# STM32L4S7xx register map
File version: 1.0
Registers are 32-bit, read-write, reset 0x0 unless marked. A register's access mark holds for its fields unless they carry their own. Offsets are from the block's base; [hi:lo] are bit positions; {n}, {i} and the like mark numbered series.

## GFXMMU — GFXMMU registers
Base 0x4002C000
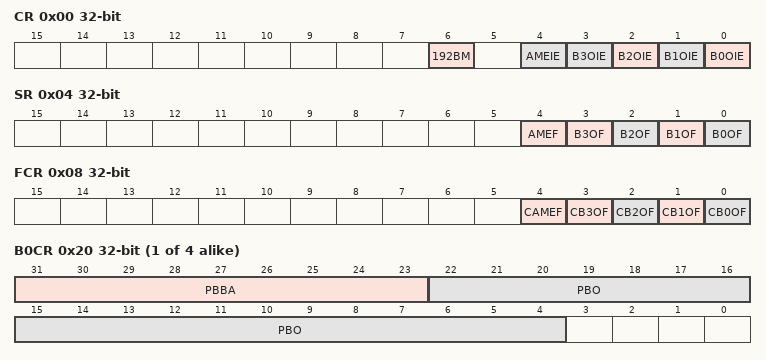
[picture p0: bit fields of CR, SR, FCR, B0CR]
0x00 CR — GFXMMU configuration register
  [6] 192BM — 192 block mode
  [4] AMEIE — AHB master error interrupt enable
  [n] B{n}OIE (n=0..3) — Buffer {n} overflow interrupt enable
0x04 SR — GFXMMU status register
  [4] AMEF — AHB master error flag
  [n] B{n}OF (n=0..3) — Buffer {n} overflow flag
0x08 FCR — GFXMMU flag clear register
  [4] CAMEF — Clear AHB master error flag
  [n] CB{n}OF (n=0..3) — Clear buffer {n} overflow flag
0x10 DVR — GFXMMU default value register
  [31:0] DV — DV[31:0] bits (Default value)
{0x20+4i} B{i}CR (i=0..3) — GFXMMU buffer {i} configuration register
  [31:23] PBBA — PBBA[31:23] bits (Physical buffer base address)
  [22:4] PBO — PB0[22:4] bits (Physical buffer offset)
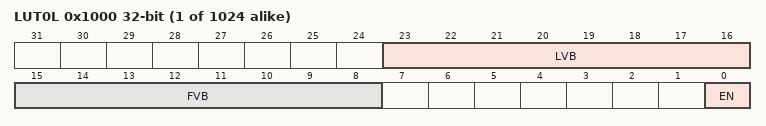
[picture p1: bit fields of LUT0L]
{0x1000+8i} LUT{i}L (i=0..1023) — GFXMMU LUT registers
  [23:16] LVB — LVB[7:0] bits (Last visible block)
  [15:8] FVB — FVB[7:0] bits (First visible block)
  [0] EN — Enable
{0x1004+8i} LUT{i}H (i=0..1023) — GFXMMU LUT registers
  [21:4] LO — LO[21:4] bits (Line offset)

## GPIOA — General Purpose I/O
Base 0x48000000
Same registers: GPIOB 0x48000400, GPIOC 0x48000800, GPIOD 0x48000C00, GPIOE 0x48001000, GPIOF 0x48001400, GPIOG 0x48001800, GPIOH 0x48001C00, GPIOI 0x48002000
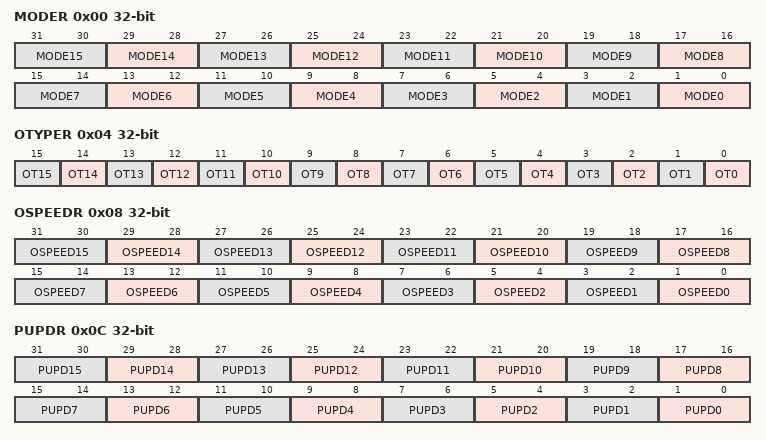
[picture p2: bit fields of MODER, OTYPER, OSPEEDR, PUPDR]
0x00 MODER — GPIO port mode register
  [2n+1:2n] MODE{n} (n=0..15)
0x04 OTYPER — GPIO port output type register
  [n] OT{n} (n=0..15)
0x08 OSPEEDR — GPIO port output speed register
  [2n+1:2n] OSPEED{n} (n=0..15)
0x0C PUPDR — GPIO port pull-up/pull-down register
  [2n+1:2n] PUPD{n} (n=0..15)
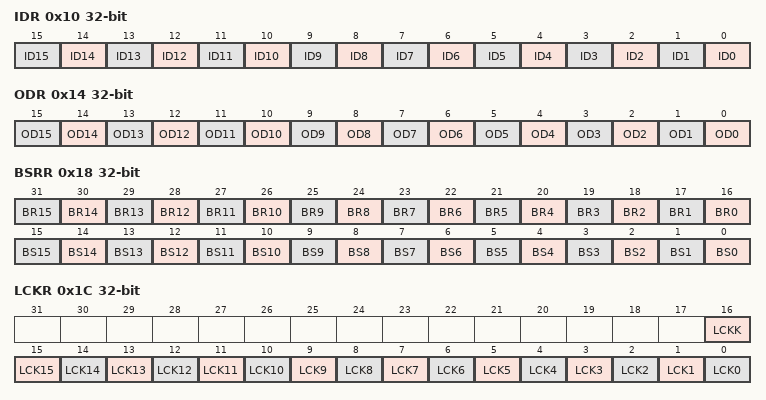
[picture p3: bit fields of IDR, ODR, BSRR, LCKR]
0x10 IDR — GPIO port input data register
  [n] ID{n} (n=0..15)
0x14 ODR — GPIO port output data register
  [n] OD{n} (n=0..15)
0x18 BSRR — GPIO port bit set/reset register
  [n+16] BR{n} (n=0..15), [n] BS{n} (n=0..15)
0x1C LCKR — GPIO port configuration lock register
  [16] LCKK, [n] LCK{n} (n=0..15)
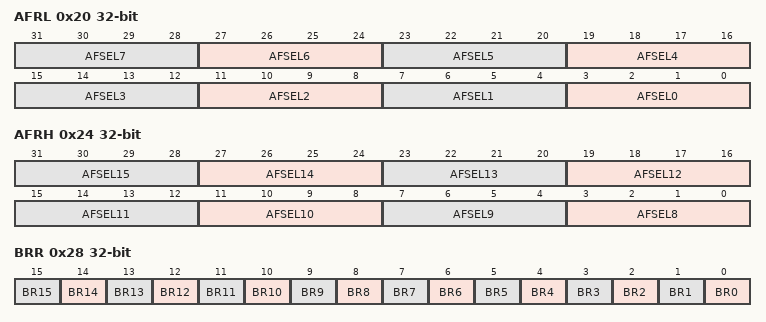
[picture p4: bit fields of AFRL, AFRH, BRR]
0x20 AFRL — GPIO alternate function registers
  [4n+3:4n] AFSEL{n} (n=0..7)
0x24 AFRH — GPIO alternate function registers
  [4n-29:4n-32] AFSEL{n} (n=8..15)
0x28 BRR — GPIO Bit Reset register
  [n] BR{n} (n=0..15)

## DCMI
Base 0x50050000
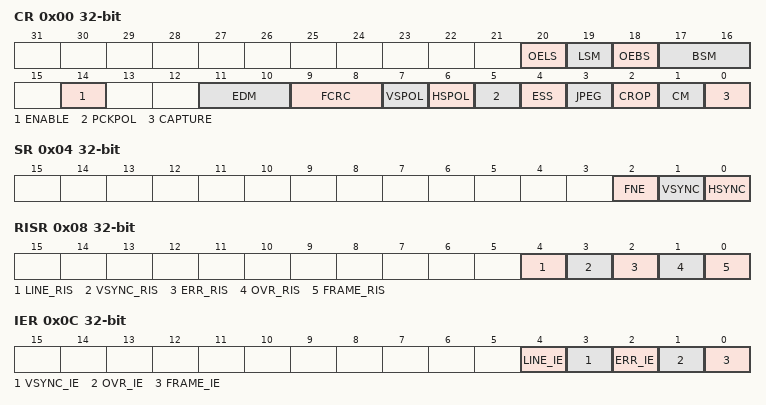
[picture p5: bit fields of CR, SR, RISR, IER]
0x00 CR — DCMI control register
  [20] OELS — DCMI Odd/Even Line Select (Line Select Start)
  [19] LSM — DCMI Line Select mode
  [18] OEBS — DCMI Odd/Even Byte Select (Byte Select Start)
  [17:16] BSM — DCMI Byte Select mode BSM[1:0]
  [14] ENABLE — DCMI DCMI enable
  [11:10] EDM — DCMI Extended data mode EDM[1:0]
  [9:8] FCRC — DCMI Frame capture rate control FCRC[1:0]
  [7] VSPOL — DCMI Vertical synchronization polarity
  [6] HSPOL — DCMI Horizontal synchronization polarity
  [5] PCKPOL — DCMI Pixel clock polarity
  [4] ESS — DCMI Embedded synchronization select
  [3] JPEG — DCMI JPEG format
  [2] CROP — DCMI Crop feature
  [1] CM — DCMI Capture mode
  [0] CAPTURE — DCMI Capture enable
0x04 SR — DCMI status register
  [2] FNE — DCMI FIFO not empty
  [1] VSYNC
  [0] HSYNC
0x08 RISR — DCMI raw interrupt status register
  [4] LINE_RIS — DCMI Line raw interrupt status
  [3] VSYNC_RIS — DCMI VSYNC raw interrupt status
  [2] ERR_RIS — DCMI Synchronization error raw interrupt status
  [1] OVR_RIS — DCMI Overrun raw interrupt status
  [0] FRAME_RIS — DCMI Capture complete raw interrupt status
0x0C IER — DCMI interrupt enable register
  [4] LINE_IE — DCMI Line interrupt enable
  [3] VSYNC_IE — DCMI VSYNC interrupt enable
  [2] ERR_IE — DCMI Synchronization error interrupt enable
  [1] OVR_IE — DCMI Overrun interrupt enable
  [0] FRAME_IE — DCMI Capture complete interrupt enable
0x0C IER_ALT (alternate view of IER) — DCMI interrupt enable register
  [4:0] INT_IE
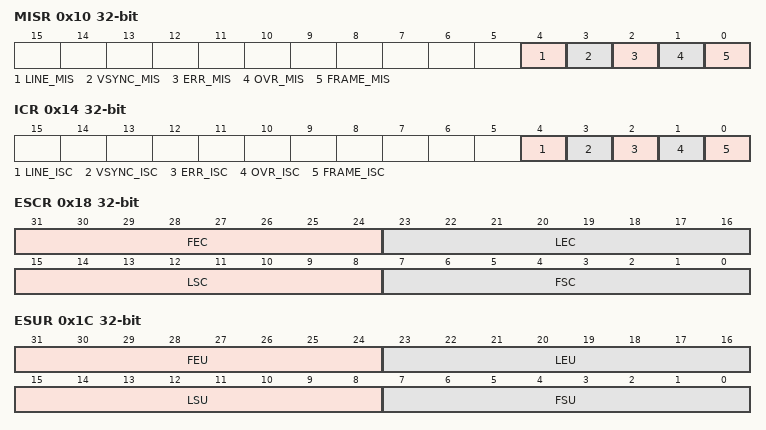
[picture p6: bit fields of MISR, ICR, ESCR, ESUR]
0x10 MISR — DCMI masked interrupt status register
  [4] LINE_MIS — DCMI Line masked interrupt status
  [3] VSYNC_MIS — DCMI VSYNC masked interrupt status
  [2] ERR_MIS — DCMI Synchronization error masked interrupt status
  [1] OVR_MIS — DCMI Overrun masked interrupt status
  [0] FRAME_MIS — DCMI Capture complete masked interrupt status
0x14 ICR — DCMI interrupt clear register
  [4] LINE_ISC — DCMI line interrupt status clear
  [3] VSYNC_ISC — DCMI Vertical synch interrupt status clear
  [2] ERR_ISC — DCMI Synchronization error interrupt status clear
  [1] OVR_ISC — DCMI Overrun interrupt status clear
  [0] FRAME_ISC — DCMI Capture complete interrupt status clear
0x18 ESCR — DCMI embedded synchronization code register
  [31:24] FEC — DCMI Frame end delimiter code FEC[7:0]
  [23:16] LEC — DCMI Line end delimiter code LEC[7:0]
  [15:8] LSC — DCMI Line start delimiter code LSC[7:0]
  [7:0] FSC — DCMI Frame start delimiter code FSC[7:0]
0x1C ESUR — DCMI embedded synchronization unmask register
  [31:24] FEU — DCMI Frame end delimiter unmask FEU[7:0]
  [23:16] LEU — DCMI Line end delimiter unmask LEU[7:0]
  [15:8] LSU — DCMI Line start delimiter unmask LSU[7:0]
  [7:0] FSU — DCMI Frame start delimiter unmask FSU[7:0]
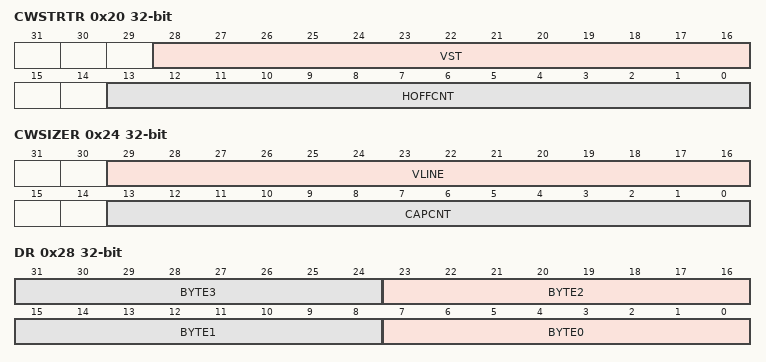
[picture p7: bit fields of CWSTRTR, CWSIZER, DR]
0x20 CWSTRTR — DCMI crop window start
  [28:16] VST — DCMI Vertical start line count VST[12:0]
  [13:0] HOFFCNT — DCMI Horizontal offset count HOFFCNT[13:0]
0x24 CWSIZER — DCMI crop window size
  [29:16] VLINE — DCMI Vertical line count VLINE[13:0]
  [13:0] CAPCNT — DCMI Capture count CAPCNT[13:0]
0x28 DR — DCMI data register
  [8n+7:8n] BYTE{n} (n=0..3) — DCMI Data byte {n} Byte{n}[7:0]
